# STM32F207 register map
File version: 1.0
CPU: CM3 r1p1, little endian, no MPU, no FPU, 4 interrupt priority bits
Registers are 32-bit, read-write, reset 0x0 unless marked. A register's access mark holds for its fields unless they carry their own. Offsets are from the block's base; [hi:lo] are bit positions; {n}, {i} and the like mark numbered series.

## DBG — Debug support
Base 0xE0042000
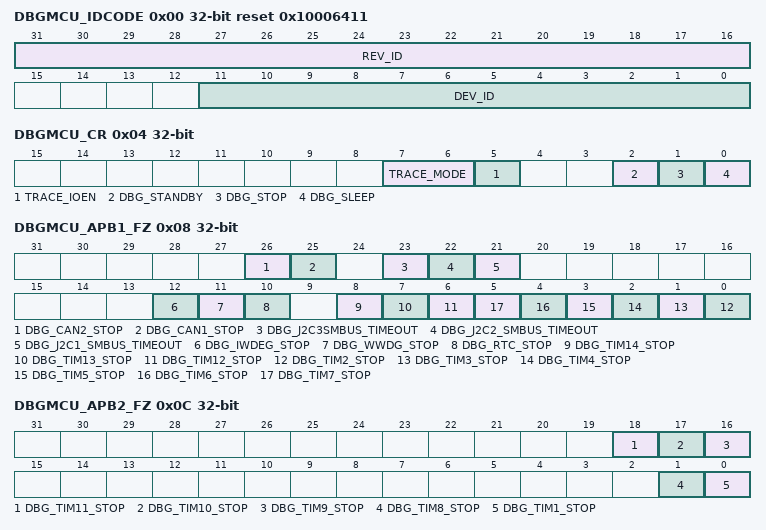
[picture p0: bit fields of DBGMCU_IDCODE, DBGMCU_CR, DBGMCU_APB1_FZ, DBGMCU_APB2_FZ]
0x00 DBGMCU_IDCODE ro reset 0x10006411 — IDCODE
  [31:16] REV_ID, [11:0] DEV_ID
0x04 DBGMCU_CR — Control Register
  [7:6] TRACE_MODE, [5] TRACE_IOEN, [2] DBG_STANDBY, [1] DBG_STOP, [0] DBG_SLEEP
0x08 DBGMCU_APB1_FZ — Debug MCU APB1 Freeze registe
  [26] DBG_CAN2_STOP, [25] DBG_CAN1_STOP, [23] DBG_J2C3SMBUS_TIMEOUT, [22] DBG_J2C2_SMBUS_TIMEOUT, [21] DBG_J2C1_SMBUS_TIMEOUT, [12] DBG_IWDEG_STOP, [11] DBG_WWDG_STOP, [10] DBG_RTC_STOP, [8] DBG_TIM14_STOP, [7] DBG_TIM13_STOP, [6] DBG_TIM12_STOP, [n-2] DBG_TIM{n}_STOP (n=2..7)
0x0C DBGMCU_APB2_FZ — Debug MCU APB2 Freeze registe
  [18] DBG_TIM11_STOP — TIM11 counter stopped when core is halted
  [17] DBG_TIM10_STOP — TIM10 counter stopped when core is halted
  [16] DBG_TIM9_STOP — TIM9 counter stopped when core is halted
  [1] DBG_TIM8_STOP — TIM8 counter stopped when core is halted
  [0] DBG_TIM1_STOP — TIM1 counter stopped when core is halted

## GPIOI — General-purpose I/Os
Base 0x40022000
Same registers: GPIOC 0x40020800, GPIOD 0x40020C00, GPIOE 0x40021000, GPIOF 0x40021400, GPIOG 0x40021800, GPIOH 0x40021C00
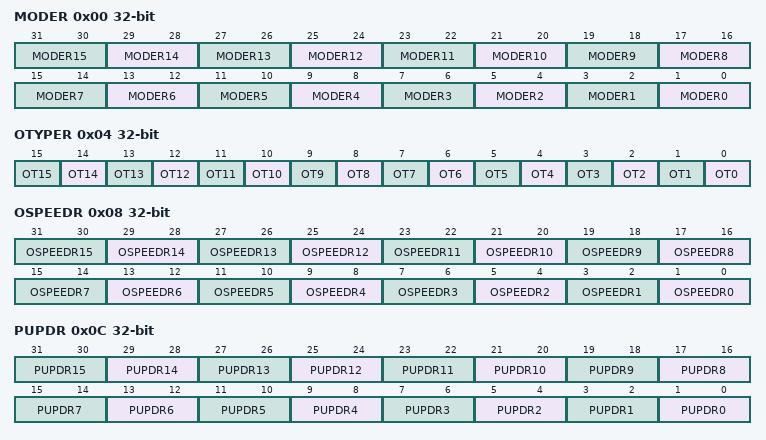
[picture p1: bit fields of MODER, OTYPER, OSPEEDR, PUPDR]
0x00 MODER — GPIO port mode register
  [2n+1:2n] MODER{n} (n=0..15) — Port x configuration bits (y = 0..15)
0x04 OTYPER — GPIO port output type register
  [n] OT{n} (n=0..15) — Port x configuration bit {n}
0x08 OSPEEDR — GPIO port output speed register
  [2n+1:2n] OSPEEDR{n} (n=0..15) — Port x configuration bits (y = 0..15)
0x0C PUPDR — GPIO port pull-up/pull-down register
  [2n+1:2n] PUPDR{n} (n=0..15) — Port x configuration bits (y = 0..15)
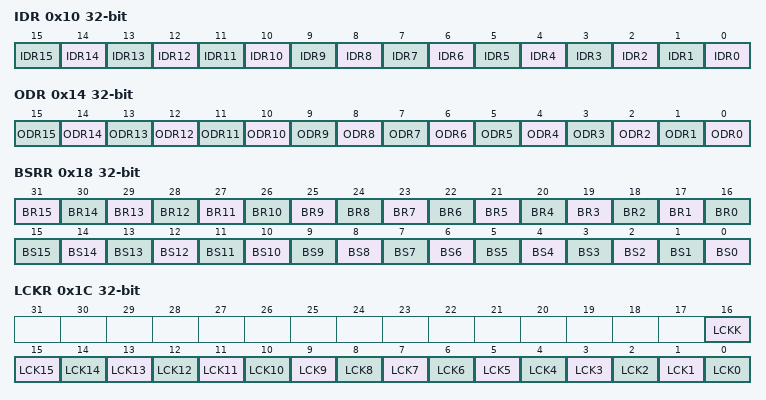
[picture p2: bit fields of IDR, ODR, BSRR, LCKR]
0x10 IDR ro — GPIO port input data register
  [n] IDR{n} (n=0..15) — Port input data (y = 0..15)
0x14 ODR — GPIO port output data register
  [n] ODR{n} (n=0..15) — Port output data (y = 0..15)
0x18 BSRR wo — GPIO port bit set/reset register
  [n+16] BR{n} (n=1..15) — Port x reset bit y (y = 0..15)
  [16] BR0 — Port x set bit y (y= 0..15)
  [n] BS{n} (n=0..15) — Port x set bit y (y= 0..15)
0x1C LCKR — GPIO port configuration lock register
  [16] LCKK — Port x lock bit y (y= 0..15)
  [n] LCK{n} (n=0..15) — Port x lock bit y (y= 0..15)
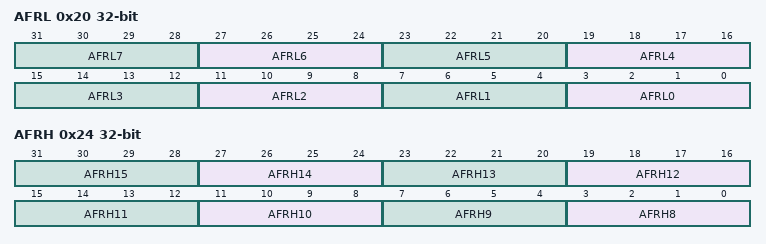
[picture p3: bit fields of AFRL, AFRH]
0x20 AFRL — GPIO alternate function low register
  [4n+3:4n] AFRL{n} (n=0..7) — Alternate function selection for port x bit y (y = 0..7)
0x24 AFRH — GPIO alternate function high register
  [4n-29:4n-32] AFRH{n} (n=8..15) — Alternate function selection for port x bit y (y = 8..15)

## GPIOB — General-purpose I/Os
Base 0x40020400
Registers as GPIOI; these are added or differ:
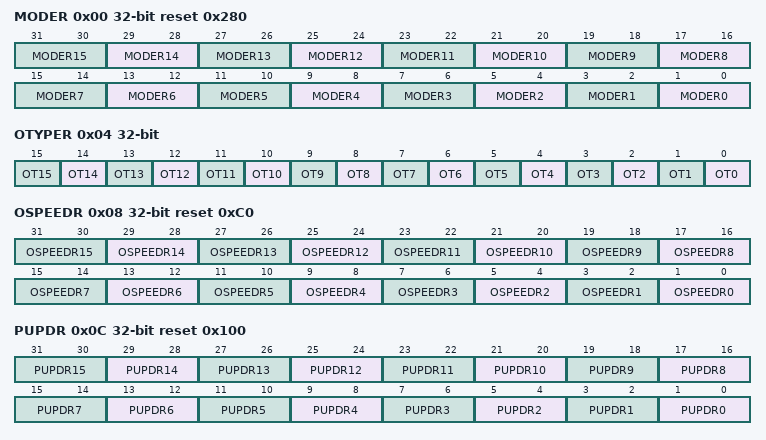
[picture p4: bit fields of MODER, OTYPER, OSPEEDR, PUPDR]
0x00 MODER reset 0x280 — GPIO port mode register
  [2n+1:2n] MODER{n} (n=0..15) — Port x configuration bits (y = 0..15)
0x04 OTYPER — GPIO port output type register
  [n] OT{n} (n=0..15) — Port x configuration bits (y = 0..15)
0x08 OSPEEDR reset 0xC0 — GPIO port output speed register
  [2n+1:2n] OSPEEDR{n} (n=0..15) — Port x configuration bits (y = 0..15)
0x0C PUPDR reset 0x100 — GPIO port pull-up/pull-down register
  [2n+1:2n] PUPDR{n} (n=0..15) — Port x configuration bits (y = 0..15)

## GPIOA — General-purpose I/Os
Base 0x40020000
Registers as GPIOI; these are added or differ:
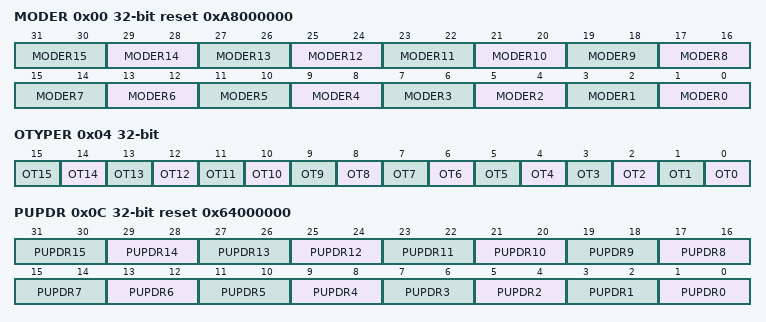
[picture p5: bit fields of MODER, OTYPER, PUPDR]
0x00 MODER reset 0xA8000000 — GPIO port mode register
  [2n+1:2n] MODER{n} (n=0..15) — Port x configuration bits (y = 0..15)
0x04 OTYPER — GPIO port output type register
  [n] OT{n} (n=0..15) — Port x configuration bits (y = 0..15)
0x0C PUPDR reset 0x64000000 — GPIO port pull-up/pull-down register
  [2n+1:2n] PUPDR{n} (n=0..15) — Port x configuration bits (y = 0..15)

## SYSCFG — System configuration controller
Base 0x40013800
0x00 MEMRM — memory remap register
  [1:0] MEM_MODE
0x04 PMC — peripheral mode configuration register
  [23] MII_RMII_SEL — Ethernet PHY interface selection
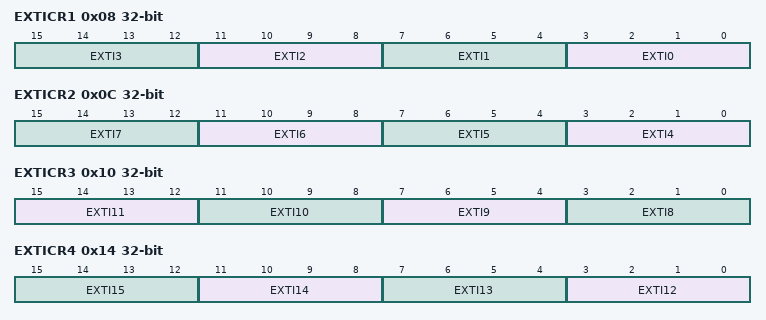
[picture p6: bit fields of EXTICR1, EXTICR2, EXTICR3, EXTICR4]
0x08 EXTICR1 — external interrupt configuration register 1
  [4n+3:4n] EXTI{n} (n=0..3) — EXTI x configuration (x = 0 to 3)
0x0C EXTICR2 — external interrupt configuration register 2
  [4n-13:4n-16] EXTI{n} (n=4..7) — EXTI x configuration (x = 4 to 7)
0x10 EXTICR3 — external interrupt configuration register 3
  [15:12] EXTI11 — EXTI x configuration (x = 8 to 11)
  [11:8] EXTI10
  [7:4] EXTI9 — EXTI x configuration (x = 8 to 11)
  [3:0] EXTI8 — EXTI x configuration (x = 8 to 11)
0x14 EXTICR4 — external interrupt configuration register 4
  [4n-45:4n-48] EXTI{n} (n=12..15) — EXTI x configuration (x = 12 to 15)
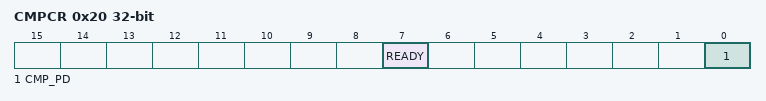
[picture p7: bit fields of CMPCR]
0x20 CMPCR access per field — Compensation cell control register
  [7] READY ro
  [0] CMP_PD rw — Compensation cell power-down

## Notices in the file
Copyright (c) 2024 STMicroelectronics.
SPDX-License-Identifier: Apache-2.0
Licensed under the Apache License, Version 2.0 (the "License");
you may not use this file except in compliance with the License.
You may obtain a copy of the License at
http://www.apache.org/licenses/LICENSE-2.0
Unless required by applicable law or agreed to in writing, software
distributed under the License is distributed on an "AS IS" BASIS,
WITHOUT WARRANTIES OR CONDITIONS OF ANY KIND, either express or implied.
See the License for the specific language governing permissions and
limitations under the License.
